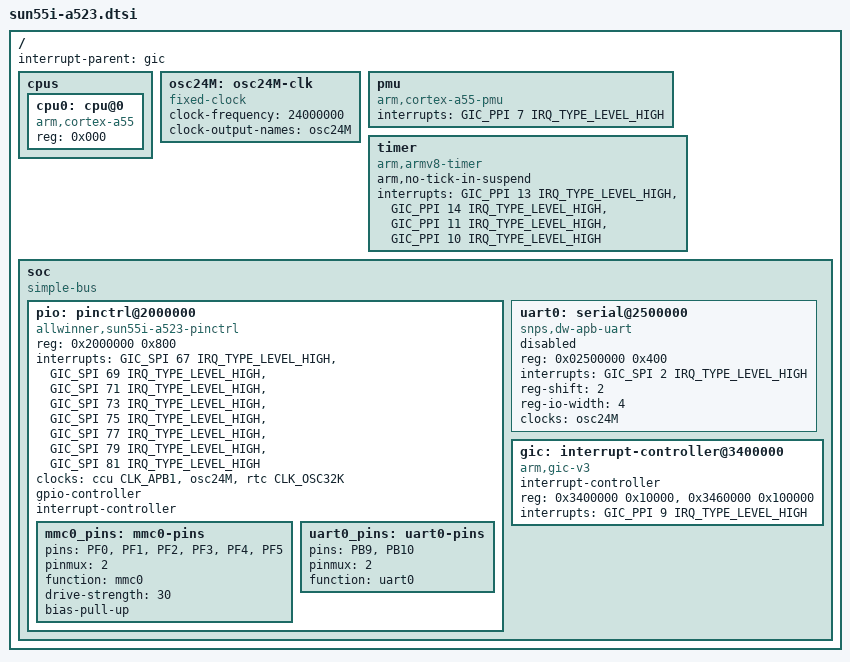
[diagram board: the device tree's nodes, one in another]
// SPDX-License-Identifier: (GPL-2.0+ OR MIT)
// Copyright (C) 2023 Arm Ltd.

#include <dt-bindings/interrupt-controller/arm-gic.h>

/ {
	interrupt-parent = <&gic>;
	#address-cells = <2>;
	#size-cells = <2>;

	cpus {
		#address-cells = <1>;
		#size-cells = <0>;

		cpu0: cpu@0 {
			compatible = "arm,cortex-a55";
			device_type = "cpu";
			reg = <0x000>;
//			enable-method = "psci";
//			clocks = <&ccu CLK_CPU_L>;
		};

#if 0
		cpu1: cpu@100 {
			compatible = "arm,cortex-a55";
			device_type = "cpu";
			reg = <0x100>;
			enable-method = "psci";
//			clocks = <&ccu CLK_CPU_L>;
		};

		cpu2: cpu@200 {
			compatible = "arm,cortex-a55";
			device_type = "cpu";
			reg = <0x200>;
			enable-method = "psci";
//			clocks = <&ccu CLK_CPU_L>;
		};

		cpu3: cpu@300 {
			compatible = "arm,cortex-a55";
			device_type = "cpu";
			reg = <0x300>;
			enable-method = "psci";
//			clocks = <&ccu CLK_CPU_L>;
		};

		cpu4: cpu@400 {
			compatible = "arm,cortex-a55";
			device_type = "cpu";
			reg = <0x400>;
			enable-method = "psci";
//			clocks = <&ccu CLK_CPU_B>;
		};

		cpu5: cpu@500 {
			compatible = "arm,cortex-a55";
			device_type = "cpu";
			reg = <0x500>;
			enable-method = "psci";
//			clocks = <&ccu CLK_CPU_B>;
		};

		cpu6: cpu@600 {
			compatible = "arm,cortex-a55";
			device_type = "cpu";
			reg = <0x600>;
			enable-method = "psci";
//			clocks = <&ccu CLK_CPU_B>;
		};

		cpu7: cpu@700 {
			compatible = "arm,cortex-a55";
			device_type = "cpu";
			reg = <0x700>;
			enable-method = "psci";
//			clocks = <&ccu CLK_CPU_B>;
		};
#endif
	};

	osc24M: osc24M-clk {
		#clock-cells = <0>;
		compatible = "fixed-clock";
		clock-frequency = <24000000>;
		clock-output-names = "osc24M";
	};

	pmu {
		compatible = "arm,cortex-a55-pmu";
		interrupts = <GIC_PPI 7 IRQ_TYPE_LEVEL_HIGH>;
	};

#if 0
	psci {
		compatible = "arm,psci-0.2";
		method = "smc";
	};
#endif

	timer {
		compatible = "arm,armv8-timer";
		arm,no-tick-in-suspend;
		interrupts = <GIC_PPI 13 IRQ_TYPE_LEVEL_HIGH>,
			     <GIC_PPI 14 IRQ_TYPE_LEVEL_HIGH>,
			     <GIC_PPI 11 IRQ_TYPE_LEVEL_HIGH>,
			     <GIC_PPI 10 IRQ_TYPE_LEVEL_HIGH>;
	};

	soc {
		compatible = "simple-bus";
		#address-cells = <1>;
		#size-cells = <1>;
		ranges = <0x0 0x0 0x0 0x40000000>;

		pio: pinctrl@2000000 {
			compatible = "allwinner,sun55i-a523-pinctrl";
			reg = <0x2000000 0x800>;
			interrupts = <GIC_SPI 67 IRQ_TYPE_LEVEL_HIGH>,
				     <GIC_SPI 69 IRQ_TYPE_LEVEL_HIGH>,
				     <GIC_SPI 71 IRQ_TYPE_LEVEL_HIGH>,
				     <GIC_SPI 73 IRQ_TYPE_LEVEL_HIGH>,
				     <GIC_SPI 75 IRQ_TYPE_LEVEL_HIGH>,
				     <GIC_SPI 77 IRQ_TYPE_LEVEL_HIGH>,
				     <GIC_SPI 79 IRQ_TYPE_LEVEL_HIGH>,
				     <GIC_SPI 81 IRQ_TYPE_LEVEL_HIGH>;
			clocks = <&ccu CLK_APB1>, <&osc24M>, <&rtc CLK_OSC32K>;
			clock-names = "apb", "hosc", "losc";
			gpio-controller;
			#gpio-cells = <3>;
			interrupt-controller;
			#interrupt-cells = <3>;

			mmc0_pins: mmc0-pins {
				pins = "PF0" ,"PF1", "PF2", "PF3", "PF4", "PF5";
				pinmux = <2>;
				function = "mmc0";
				drive-strength = <30>;
				bias-pull-up;
			};

			uart0_pins: uart0-pins {
				pins = "PB9", "PB10";
				pinmux = <2>;
				function = "uart0";
                        };

		};

		uart0: serial@2500000 {
			compatible = "snps,dw-apb-uart";
			reg = <0x02500000 0x400>;
			interrupts = <GIC_SPI 2 IRQ_TYPE_LEVEL_HIGH>;
			reg-shift = <2>;
			reg-io-width = <4>;
			clocks = <&osc24M>;
//			clocks = <&ccu CLK_BUS_UART0>;
//			resets = <&ccu RST_BUS_UART0>;
			status = "disabled";
		};

		gic: interrupt-controller@3400000 {
			compatible = "arm,gic-v3";
			#address-cells = <0>;
			#interrupt-cells = <3>;
			interrupt-controller;
			reg = <0x3400000 0x10000>,
			      <0x3460000 0x100000>;
			interrupts = <GIC_PPI 9 IRQ_TYPE_LEVEL_HIGH>;
		};
	};
};
